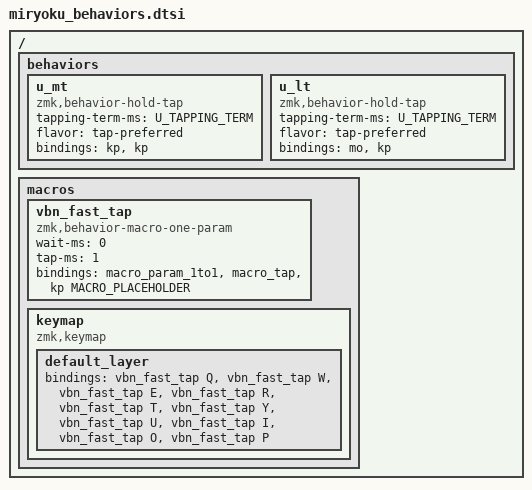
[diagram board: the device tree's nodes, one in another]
// Copyright 2022 Manna Harbour
// https://github.com/manna-harbour/miryoku

/ {
  behaviors {
    u_mt: u_mt {
      compatible = "zmk,behavior-hold-tap";
      #binding-cells = <2>;
      tapping-term-ms = <U_TAPPING_TERM>;
      flavor = "tap-preferred";
      bindings = <&kp>, <&kp>;
    };
    u_lt: u_lt {
      compatible = "zmk,behavior-hold-tap";
      #binding-cells = <2>;
      tapping-term-ms = <U_TAPPING_TERM>;
      flavor = "tap-preferred";
      bindings = <&mo>, <&kp>;
    };
  };
  macros {
    vbn_fast_tap: vbn_fast_tap {
      compatible = "zmk,behavior-macro-one-param";
      #binding-cells = <1>;
      wait-ms = <0>;
      tap-ms = <1>;
      bindings = <&macro_param_1to1 &macro_tap &kp MACRO_PLACEHOLDER>;
    };
    keymap {
        compatible = "zmk,keymap";
        default_layer {
            bindings = <
                &vbn_fast_tap Q  &vbn_fast_tap W  &vbn_fast_tap E  &vbn_fast_tap R &vbn_fast_tap T &vbn_fast_tap Y &vbn_fast_tap U &vbn_fast_tap I &vbn_fast_tap O &vbn_fast_tap P
            >;
        };
    };
  };
};
